# STM32F103 register map
File version: 1.1
CPU: CM3 r1p1, little endian, no MPU, no FPU, 4 interrupt priority bits
Registers are 32-bit, read-write, reset 0x0 unless marked. A register's access mark holds for its fields unless they carry their own. Offsets are from the block's base; [hi:lo] are bit positions; {n}, {i} and the like mark numbered series; 'fields as' and 'values as' point back to an identical list.

## DAC — Digital to analog converter
Base 0x40007400
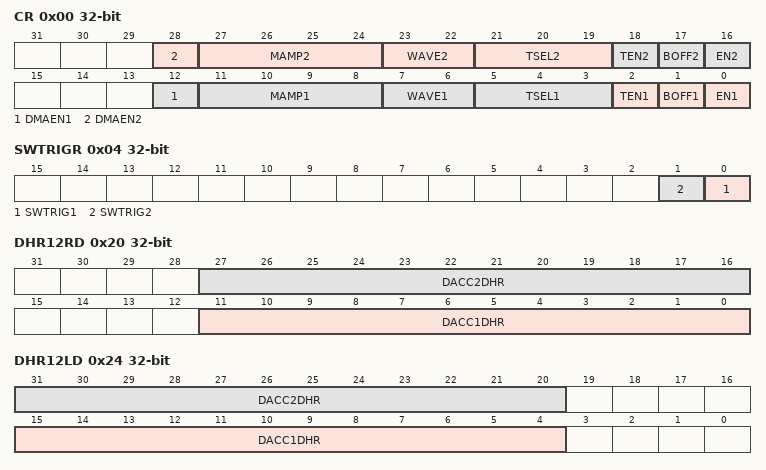
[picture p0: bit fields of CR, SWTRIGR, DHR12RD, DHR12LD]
0x00 CR — Control register (DAC_CR)
  [21:19] TSEL2 — DAC channel2 trigger selection
    0=Tim6Trgo (Timer 6 TRGO event); 1=Tim8Trgo (Timer 8 TRGO event); 2=Tim7Trgo (Timer 7 TRGO event); 3=Tim5Trgo (Timer 5 TRGO event); 4=Tim2Trgo (Timer 2 TRGO event); 5=Tim4Trgo (Timer 4 TRGO event); 6=Exti9 (EXTI line 9); 7=Swtrig (Software trigger)
  [16n-4] DMAEN{n} (n=1..2) — DAC channel{n} DMA enable
    0=Disabled (DAC channel X DMA mode disabled); 1=Enabled (DAC channel X DMA mode enabled)
  [16n-5:16n-8] MAMP{n} (n=1..2) — DAC channel{n} mask/amplitude selector
    0=Amp1 (Unmask bit0 of LFSR/ triangle amplitude equal to 1); 1=Amp3 (Unmask bits[1:0] of LFSR/ triangle amplitude equal to 3); 2=Amp7 (Unmask bits[2:0] of LFSR/ triangle amplitude equal to 7); 3=Amp15 (Unmask bits[3:0] of LFSR/ triangle amplitude equal to 15); 4=Amp31 (Unmask bits[4:0] of LFSR/ triangle amplitude equal to 31); 5=Amp63 (Unmask bits[5:0] of LFSR/ triangle amplitude equal 63); 6=Amp127 (Unmask bits[6:0] of LFSR/ triangle amplitude equal to 127); 7=Amp255 (Unmask bits[7:0] of LFSR/ triangle amplitude equal to 255); 8=Amp511 (Unmask bits[8:0] of LFSR/ triangle amplitude equal to 511); 9=Amp1023 (Unmask bits[9:0] of LFSR/ triangle amplitude equal to 1023); 10=Amp2047 (Unmask bits[10:0] of LFSR/ triangle amplitude equal to 2047); other=Amp4095 (Unmask bits[11:0] of LFSR/ triangle amplitude equal to 4095)
  [16n-9:16n-10] WAVE{n} (n=1..2) — DAC channel{n} noise/triangle wave generation enable
    0=Disabled (Wave generation disabled); 1=Noise wave generation enabled; other=Triangle wave generation enabled
  [5:3] TSEL1 — DAC channel1 trigger selection
    values as TSEL2
  [16n-14] TEN{n} (n=1..2) — DAC channel{n} trigger enable
    0=Disabled (DAC channel X trigger disabled); 1=Enabled (DAC channel X trigger enabled)
  [16n-15] BOFF{n} (n=1..2) — DAC channel{n} output buffer disable
    0=Enabled (DAC channel X output buffer enabled); 1=Disabled (DAC channel X output buffer disabled)
  [16n-16] EN{n} (n=1..2) — DAC channel{n} enable
    0=Disabled (DAC channel X disabled); 1=Enabled (DAC channel X enabled)
0x04 SWTRIGR wo — DAC software trigger register (DAC_SWTRIGR)
  [n-1] SWTRIG{n} (n=1..2) — DAC channel{n} software trigger
    0=Disabled (DAC channel X software trigger disabled); 1=Enabled (DAC channel X software trigger enabled)
0x08 DHR12R{i} (i=1..2; step 0xC) — channel{i} 12-bit right-aligned data holding register
  [11:0] DACCDHR — DAC channel1 12-bit right-aligned data
{0x0+0xC*i} DHR12L{i} (i=1..2) — channel{i} 12-bit left aligned data holding register
  [15:4] DACCDHR — DAC channel1 12-bit left-aligned data
{0x4+0xC*i} DHR8R{i} (i=1..2) — channel{i} 8-bit right aligned data holding register
  [7:0] DACCDHR — DAC channel1 8-bit right-aligned data
0x20 DHR12RD — Dual DAC 12-bit right-aligned data holding register (DAC_DHR12RD), Bits 31:28 Reserved, Bits 15:12 Reserved
  [16n-5:16n-16] DACC{n}DHR (n=1..2) — DAC channel{n} 12-bit right-aligned data
0x24 DHR12LD — DUAL DAC 12-bit left aligned data holding register (DAC_DHR12LD), Bits 19:16 Reserved, Bits 3:0 Reserved
  [16n-1:16n-12] DACC{n}DHR (n=1..2) — DAC channel{n} 12-bit left-aligned data
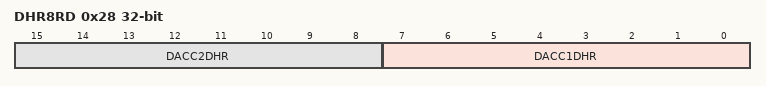
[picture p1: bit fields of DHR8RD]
0x28 DHR8RD — DUAL DAC 8-bit right aligned data holding register (DAC_DHR8RD), Bits 31:16 Reserved
  [8n-1:8n-8] DACC{n}DHR (n=1..2) — DAC channel{n} 8-bit right-aligned data
{0x28+4i} DOR{i} (i=1..2) ro — channel{i} data output register
  [11:0] DACCDOR — DAC channel1 data output

## DBGMCU — Debug support
Base 0xE0042000
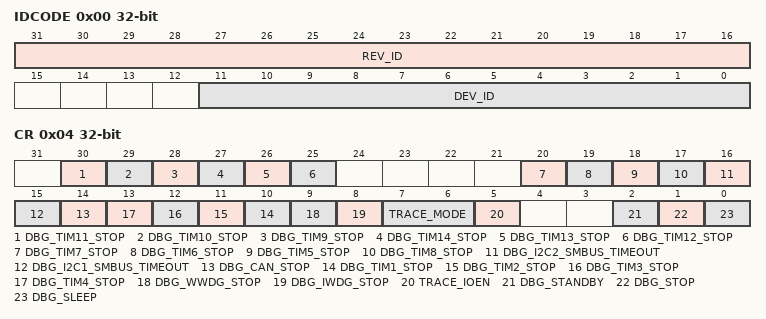
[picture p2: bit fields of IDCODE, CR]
0x00 IDCODE ro — DBGMCU_IDCODE
  [31:16] REV_ID, [11:0] DEV_ID
0x04 CR — DBGMCU_CR
  [30] DBG_TIM11_STOP — TIM11 counter stopped when core is halted
  [29] DBG_TIM10_STOP — TIM10 counter stopped when core is halted
  [28] DBG_TIM9_STOP — TIM9 counter stopped when core is halted
  [27] DBG_TIM14_STOP — TIM14 counter stopped when core is halted
  [26] DBG_TIM13_STOP — TIM13 counter stopped when core is halted
  [25] DBG_TIM12_STOP — TIM12 counter stopped when core is halted
  [20] DBG_TIM7_STOP
  [19] DBG_TIM6_STOP
  [18] DBG_TIM5_STOP
  [17] DBG_TIM8_STOP
  [16] DBG_I2C2_SMBUS_TIMEOUT
  [15] DBG_I2C1_SMBUS_TIMEOUT
  [14] DBG_CAN_STOP
  [n+9] DBG_TIM{n}_STOP (n=1..4)
  [9] DBG_WWDG_STOP
  [8] DBG_IWDG_STOP
  [7:6] TRACE_MODE
  [5] TRACE_IOEN
  [2] DBG_STANDBY
  [1] DBG_STOP
  [0] DBG_SLEEP
